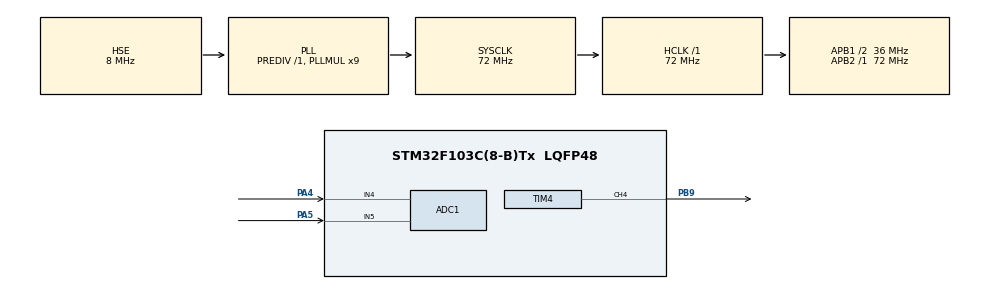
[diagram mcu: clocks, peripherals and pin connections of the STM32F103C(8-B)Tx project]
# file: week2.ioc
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ADC1.Channel-2\#ChannelRegularConversion=ADC_CHANNEL_4
ADC1.Channel-3\#ChannelRegularConversion=ADC_CHANNEL_5
ADC1.DiscontinuousConvMode=ENABLE
ADC1.NbrOfConversion=2
ADC1.NbrOfConversionFlag=1
ADC1.Rank-2\#ChannelRegularConversion=1
ADC1.Rank-3\#ChannelRegularConversion=2
ADC1.SamplingTime-2\#ChannelRegularConversion=ADC_SAMPLETIME_55CYCLES_5
ADC1.SamplingTime-3\#ChannelRegularConversion=ADC_SAMPLETIME_55CYCLES_5
ADC1.master=1
Mcu.Family=STM32F1
Mcu.Name=STM32F103C(8-B)Tx
Mcu.Package=LQFP48
NVIC.PriorityGroup=NVIC_PRIORITYGROUP_4
PA13.Mode=Serial_Wire
PA13.Signal=SYS_JTMS-SWDIO
PA14.Mode=Serial_Wire
PA14.Signal=SYS_JTCK-SWCLK
PA4.Signal=ADCx_IN4
PA5.Signal=ADCx_IN5
PB9.Signal=S_TIM4_CH4
PD0-OSC_IN.Mode=HSE-External-Oscillator
PD0-OSC_IN.Signal=RCC_OSC_IN
PD1-OSC_OUT.Mode=HSE-External-Oscillator
PD1-OSC_OUT.Signal=RCC_OSC_OUT
ProjectManager.HeapSize=0x200
ProjectManager.StackSize=0x400
ProjectManager.TargetToolchain=Makefile
RCC.ADCPresc=RCC_ADCPCLK2_DIV6
RCC.AHBFreq_Value=72000000
RCC.APB1CLKDivider=RCC_HCLK_DIV2
RCC.APB1Freq_Value=36000000
RCC.APB1TimFreq_Value=72000000
RCC.APB2Freq_Value=72000000
RCC.APB2TimFreq_Value=72000000
RCC.HCLKFreq_Value=72000000
RCC.PLLMUL=RCC_PLL_MUL9
RCC.PLLSourceVirtual=RCC_PLLSOURCE_HSE
RCC.SYSCLKFreq_VALUE=72000000
RCC.SYSCLKSource=RCC_SYSCLKSOURCE_PLLCLK
RCC.USBFreq_Value=72000000
SH.ADCx_IN4.0=ADC1_IN4,IN4
SH.ADCx_IN5.0=ADC1_IN5,IN5
SH.S_TIM4_CH4.0=TIM4_CH4,PWM Generation4 CH4
TIM4.Channel-PWM\ Generation4\ CH4=TIM_CHANNEL_4
TIM4.Period=20000-1
TIM4.Prescaler=72-1
TIM4.Pulse-PWM\ Generation4\ CH4=150
VP_TIM4_VS_ClockSourceINT.Mode=Internal
board=custom

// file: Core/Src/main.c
/* USER CODE BEGIN Header */
/**
  ******************************************************************************
  * @file           : main.c
  * @brief          : Main program body
  ******************************************************************************
  * @attention
  *
  * Copyright (c) 2026 STMicroelectronics.
  * All rights reserved.
  *
  * This software is licensed under terms that can be found in the LICENSE file
  * in the root directory of this software component.
  * If no LICENSE file comes with this software, it is provided AS-IS.
  *
  ******************************************************************************
  */
/* USER CODE END Header */
#include "main.h"
#include "adc.h"
#include "tim.h"
#include "gpio.h"

/* USER CODE BEGIN PD */
#define ADC_CENTER 2054U
#define ADC_DEADBAND 30U
#define SERVO_MIN 500U
#define SERVO_MAX 2500U
/* USER CODE END PD */

/* USER CODE BEGIN PV */
static volatile uint16_t adc_x =0U;
static volatile uint16_t adc_y =0U;
static volatile uint16_t servo_ccr =1500U;
/* USER CODE END PV */

void SystemClock_Config(void);

int main(void)
{

  /* MCU Configuration--------------------------------------------------------*/

  /* Reset of all peripherals, Initializes the Flash interface and the Systick. */
  HAL_Init();

  /* Configure the system clock */
  SystemClock_Config();

  /* Initialize all configured peripherals */
  MX_GPIO_Init();
  MX_ADC1_Init();
  MX_TIM4_Init();
  /* USER CODE BEGIN 2 */
  __HAL_TIM_SET_COMPARE(&htim4,TIM_CHANNEL_4,1500U);
  HAL_TIM_PWM_Start(&htim4,TIM_CHANNEL_4);
  HAL_ADCEx_Calibration_Start(&hadc1);
  /* USER CODE END 2 */

  /* Infinite loop */
  while (1)
  {

    /* USER CODE BEGIN 3 */

    // __HAL_TIM_SET_COMPARE(&htim4,TIM_CHANNEL_4,50U);
    // HAL_Delay(1000U);
    // __HAL_TIM_SET_COMPARE(&htim4,TIM_CHANNEL_4,150U);
    // HAL_Delay(1000U);
    // __HAL_TIM_SET_COMPARE(&htim4,TIM_CHANNEL_4,250U);
    // HAL_Delay(1000U);
    // __HAL_TIM_SET_COMPARE(&htim4,TIM_CHANNEL_4,150U);
    // HAL_Delay(1000U);

    uint16_t x =0U;
    uint16_t y =0U;
    uint32_t target =1500U;
    int32_t offset =0;

    HAL_ADC_Start(&hadc1);
    if(HAL_ADC_PollForConversion(&hadc1,50U)==HAL_OK)
    {
      x=(uint16_t)HAL_ADC_GetValue(&hadc1);
    }

    HAL_ADC_Start(&hadc1);
    if(HAL_ADC_PollForConversion(&hadc1,50U)==HAL_OK)
    {
      y=(uint16_t)HAL_ADC_GetValue(&hadc1);
    }

    adc_x=x;
    adc_y=y;

    offset=(int32_t)x-(int32_t)ADC_CENTER;
    if((offset>-(int32_t)ADC_DEADBAND)&&(offset<(int32_t)ADC_DEADBAND))
    {
      target =1500U;
    }
    else
    {
      target=500U+((uint32_t)x*2000U)/4095U;
    }

    if(target<SERVO_MIN)
    {
      target=SERVO_MIN;
    }
    if(target>SERVO_MAX)
    {
      target=SERVO_MAX;
    }

    servo_ccr=(uint16_t)target;

    __HAL_TIM_SET_COMPARE(&htim4,TIM_CHANNEL_4,(uint16_t)target);

    HAL_Delay(20U);

  }
  /* USER CODE END 3 */
}

void SystemClock_Config(void)
{
  RCC_OscInitTypeDef RCC_OscInitStruct = {0};
  RCC_ClkInitTypeDef RCC_ClkInitStruct = {0};
  RCC_PeriphCLKInitTypeDef PeriphClkInit = {0};

  /** Initializes the RCC Oscillators according to the specified parameters
  * in the RCC_OscInitTypeDef structure.
  */
  RCC_OscInitStruct.OscillatorType = RCC_OSCILLATORTYPE_HSE;
  RCC_OscInitStruct.HSEState = RCC_HSE_ON;
  RCC_OscInitStruct.HSEPredivValue = RCC_HSE_PREDIV_DIV1;
  RCC_OscInitStruct.HSIState = RCC_HSI_ON;
  RCC_OscInitStruct.PLL.PLLState = RCC_PLL_ON;
  RCC_OscInitStruct.PLL.PLLSource = RCC_PLLSOURCE_HSE;
  RCC_OscInitStruct.PLL.PLLMUL = RCC_PLL_MUL9;
  if (HAL_RCC_OscConfig(&RCC_OscInitStruct) != HAL_OK)
  {
    Error_Handler();
  }

  /** Initializes the CPU, AHB and APB buses clocks
  */
  RCC_ClkInitStruct.ClockType = RCC_CLOCKTYPE_HCLK|RCC_CLOCKTYPE_SYSCLK
                              |RCC_CLOCKTYPE_PCLK1|RCC_CLOCKTYPE_PCLK2;
  RCC_ClkInitStruct.SYSCLKSource = RCC_SYSCLKSOURCE_PLLCLK;
  RCC_ClkInitStruct.AHBCLKDivider = RCC_SYSCLK_DIV1;
  RCC_ClkInitStruct.APB1CLKDivider = RCC_HCLK_DIV2;
  RCC_ClkInitStruct.APB2CLKDivider = RCC_HCLK_DIV1;

  if (HAL_RCC_ClockConfig(&RCC_ClkInitStruct, FLASH_LATENCY_2) != HAL_OK)
  {
    Error_Handler();
  }
  PeriphClkInit.PeriphClockSelection = RCC_PERIPHCLK_ADC;
  PeriphClkInit.AdcClockSelection = RCC_ADCPCLK2_DIV6;
  if (HAL_RCCEx_PeriphCLKConfig(&PeriphClkInit) != HAL_OK)
  {
    Error_Handler();
  }
}

void Error_Handler(void)
{
  __disable_irq();
  while (1)
  {
  }
}
